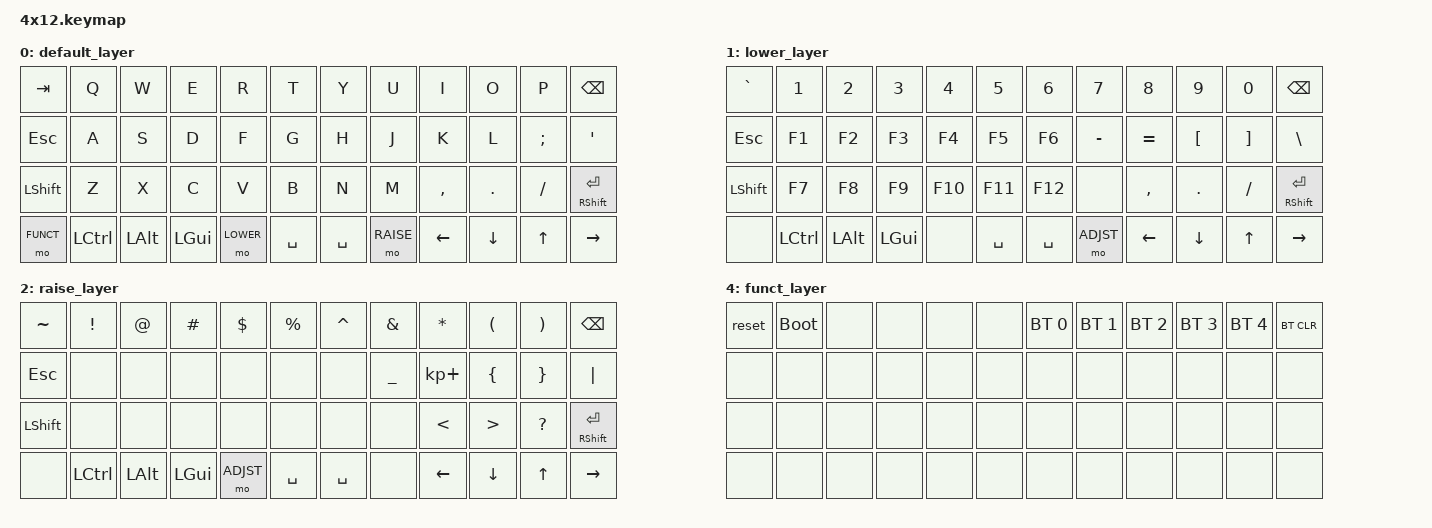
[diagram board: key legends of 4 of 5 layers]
/*
 * Copyright (c 2021 The ZMK Contributors
 *
 * SPDX-License-Identifier: MIT
 */

#include <behaviors.dtsi>
#include <dt-bindings/zmk/keys.h>
#include <dt-bindings/zmk/bt.h>

#define DEFAULT 0
#define LOWER   1
#define RAISE   2
#define ADJST   3
#define FUNCT   4

/ {
    behaviors {
        hm: homerow_mods {
            compatible = "zmk,behavior-hold-tap";
            label = "HOMEROW_MODS";
            #binding-cells = <2>;
            tapping-term-ms = <150>;
            quick_tap_ms = <0>;
            flavor = "tap-preferred";
            bindings = <&kp>, <&kp>;
        };
    };
    
	keymap {
		compatible = "zmk,keymap";

		default_layer {
				// -----------------------------------------------------------------------------------------
				// |  TAB  |  Q   |  W   |  E   |  R   |  T    |   Y   |  U    |  I   |  O   |   P   | BSPC  |
				// |  ESC  |  A   |  S   |  D   |  F   |  G    |   H   |  J    |  K   |  L   |   ;   |  '    |
				// | SHIFT |  Z   |  X   |  C   |  V   |  B    |   N   |  M    |  ,   |  .   |   /   |  RET  |
				// | FUNCT | LCTL | LALT | LGUI | LOWR | SPACE | SPACE |  RAIS | LEFT | DOWN |  UP   |  RGHT |
			bindings = <
				&kp TAB  &kp Q    &kp W &kp E &kp R &kp T  &kp Y   &kp U  &kp I    &kp O   &kp P    &kp BSPC
				&kp ESC  &kp A    &kp S &kp D &kp F &kp G  &kp H   &kp J  &kp K    &kp L   &kp SEMI &kp SQT
				&kp LSHFT &kp Z    &kp X &kp C &kp V &kp B  &kp N   &kp M  &kp COMMA &kp DOT &kp FSLH &mt RSHFT RET
				&mo FUNCT &kp LCTRL &kp LALT &kp LGUI &mo LOWER &kp SPACE &kp SPACE &mo RAISE &kp LEFT &kp DOWN &kp UP &kp RIGHT
			>;
		};

		lower_layer {
			bindings = <
				&kp GRAVE &kp N1 &kp N2 &kp N3 &kp N4 &kp N5 &kp N6 &kp N7 &kp N8 &kp N9 &kp N0 &kp BSPC
				&kp ESC &kp F1 &kp F2 &kp F3 &kp F4 &kp F5 &kp F6 &kp MINUS &kp EQUAL &kp LBKT &kp RBKT &kp BSLH
				&kp LSHFT &kp F7 &kp F8 &kp F9 &kp F10 &kp F11 &kp F12 &none &kp COMMA &kp DOT &kp FSLH &mt RSHFT RET
				&none &kp LCTRL &kp LALT &kp LGUI &none &kp SPACE &kp SPACE &mo ADJST &kp LEFT &kp DOWN &kp UP &kp RIGHT
			>;
		};

		raise_layer {
			bindings = <
				&kp TILDE &kp EXCL &kp AT &kp HASH &kp DLLR &kp PRCNT &kp CARET &kp AMPS &kp ASTRK &kp LPAR &kp RPAR &kp BSPC
				&kp ESC &none &none &none &none &none &none &kp UNDER &kp KP_PLUS &kp LBRC &kp RBRC &kp PIPE
				&kp LSHFT &none &none &none &none &none &none &none &kp LT &kp GT &kp QMARK &mt RSHFT RET
				&none &kp LCTRL &kp LALT &kp LGUI &mo ADJST &kp SPACE &kp SPACE &none &kp LEFT &kp DOWN &kp UP &kp RIGHT
			>;
		};
		
		adjust_layer {
			bindings = <
				&none &none &none &kp C_BRI_DN &kp C_BRI_UP &none &kp F1 &kp F2 &kp F3 &kp F4 &kp F5 &kp F6
				&none &none &none &kp C_VOL_DN &kp C_VOL_UP &kp C_MUTE &kp F7 &kp F8 &kp F9 &kp F10 &kp F11 &kp F12
				&none &none &none &none &none &none &none &none &none &none &none &none
				&none &none &none &none &none &none &none &none &none &none &none &none
				&none &none &none &none &none &none &none &none &none &none &none &none
			>;
		};
		
		funct_layer {
			bindings = <
				&reset &bootloader &none &none &none &none &bt BT_SEL 0 &bt BT_SEL 1 &bt BT_SEL 2 &bt BT_SEL 3 &bt BT_SEL 4 &bt BT_CLR
				&none &none &none &none &none &none &none &none &none &none &none &none
				&none &none &none &none &none &none &none &none &none &none &none &none
				&none &none &none &none &none &none &none &none &none &none &none &none
			>;
		};
	};
};
